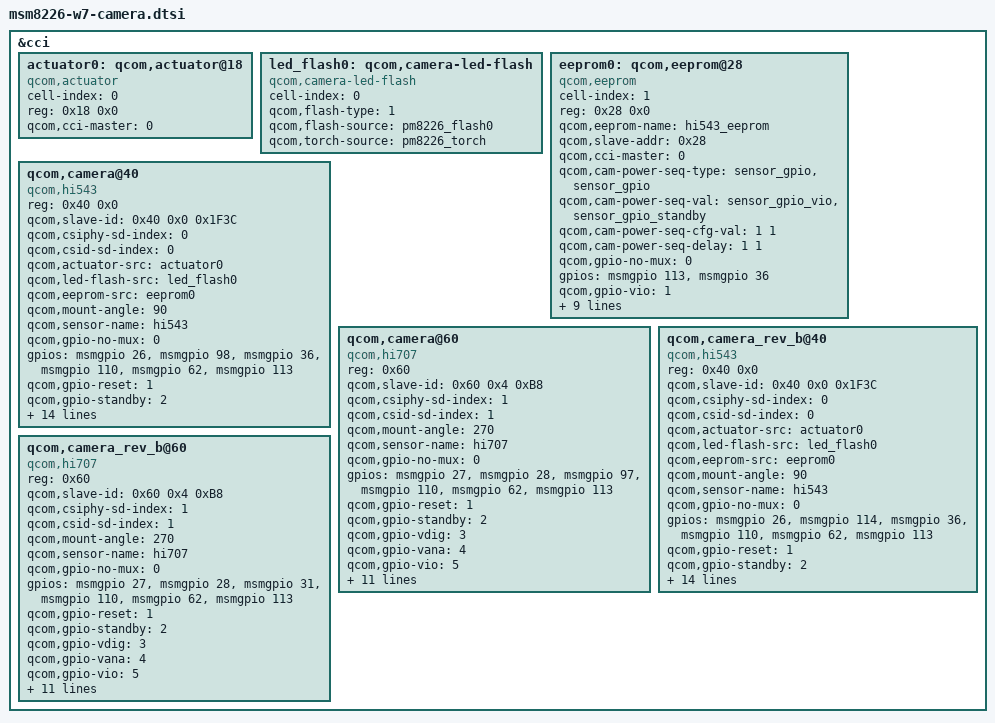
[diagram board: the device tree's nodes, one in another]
/*
 * Copyright (c) 2013, The Linux Foundation. All rights reserved.
 *
 * This program is free software; you can redistribute it and/or modify
 * it under the terms of the GNU General Public License version 2 and
 * only version 2 as published by the Free Software Foundation.
 *
 * This program is distributed in the hope that it will be useful,
 * but WITHOUT ANY WARRANTY; without even the implied warranty of
 * MERCHANTABILITY or FITNESS FOR A PARTICULAR PURPOSE.  See the
 * GNU General Public License for more details.
 */

&cci {
	actuator0: qcom,actuator@18 {
		cell-index = <0>;	//Use Af_main_0 of dw9716 with HI543
		reg = <0x18 0x0>;
		compatible = "qcom,actuator";
		qcom,cci-master = <0>;
	};

	led_flash0: qcom,camera-led-flash {
		cell-index = <0>;
		compatible = "qcom,camera-led-flash";
		qcom,flash-type = <1>;
		qcom,flash-source = <&pm8226_flash0>;
                qcom,torch-source = <&pm8226_torch>;
	};

	eeprom0: qcom,eeprom@28 { //EEPROM READ
		cell-index = <1>;
		reg = <0x28 0x0>;
		qcom,eeprom-name = "hi543_eeprom";
		compatible = "qcom,eeprom";
		qcom,slave-addr = <0x28>;
		qcom,cci-master = <0>;

		qcom,cam-power-seq-type = "sensor_gpio","sensor_gpio";
		qcom,cam-power-seq-val = "sensor_gpio_vio","sensor_gpio_standby";
		qcom,cam-power-seq-cfg-val = <1 1>;
		qcom,cam-power-seq-delay = <1 1>;
		qcom,gpio-no-mux = <0>;
		gpios = <&msmgpio 113 0>,	//1.8V IOVDD
			<&msmgpio 36 0>;		//2.8V VCM
		qcom,gpio-vio = <1>;
		qcom,gpio-standby = <0>;		//CAM_STANDBY
		qcom,gpio-req-tbl-num = <0 1>;
		qcom,gpio-req-tbl-flags = <0 0>;
		qcom,gpio-req-tbl-label = "MAIN_VIO_EN","CAM_STANDBY";

		qcom,num-blocks = <1>;
		qcom,page0 = <0 0x0 1 0x0 1 20>; // valid size, addr, addr_t, data, data_t, delay
		qcom,poll0 = <0 0x0 1 0x0 1 20>;
		qcom,mem0  = <0x06 0x0000 2 0 1 0>; //EEPROM READ
	};

	/* Rev A */
	qcom,camera@40 {
		compatible = "qcom,hi543";
		reg = <0x40 0x0>;
		qcom,slave-id = <0x40 0x0 0x1F3C>;
		qcom,csiphy-sd-index = <0>;
		qcom,csid-sd-index = <0>;
		qcom,actuator-src = <&actuator0>;
		qcom,led-flash-src = <&led_flash0>;
		qcom,eeprom-src = <&eeprom0>;
		qcom,mount-angle = <90>;
		qcom,sensor-name = "hi543";
		qcom,gpio-no-mux = <0>;
		gpios = <&msmgpio 26 0>,
			<&msmgpio 98 0>,
			<&msmgpio 36 0>,
			<&msmgpio 110 0>,	//1.8V DVDD
			<&msmgpio 62 0>,	//2.8V AVDD & 2.8V VCM
			<&msmgpio 113 0>;	//1.8V IOVDD
		qcom,gpio-reset = <1>;
		qcom,gpio-standby = <2>;
		qcom,gpio-vdig = <3>;
		qcom,gpio-vana = <4>;
		qcom,gpio-vio = <5>;
		qcom,gpio-req-tbl-num = <0 1 2 3 4 5>;
		qcom,gpio-req-tbl-flags = <1 0 0 0 0 0>;
		qcom,gpio-req-tbl-label = "CAMIF_MCLK", "CAM_RESET1", "CAM_STANDBY", "MAIN_VDIG_EN", "MAIN_VANA_EN", "MAIN_VIO_EN";
		qcom,csi-lane-assign = <0x4320>;
		qcom,csi-lane-mask = <0x07>;
		qcom,sensor-position = <0>;
		qcom,sensor-mode = <1>;
		qcom,cci-master = <0>;
		status = "okay";
		revision = "...rev_a";
	};
	qcom,camera@60 {
		compatible = "qcom,hi707";
		reg = <0x60>;
		qcom,slave-id = <0x60 0x4 0xB8>;
		qcom,csiphy-sd-index = <1>;
		qcom,csid-sd-index = <1>;
		qcom,mount-angle = <270>;
		qcom,sensor-name = "hi707";
		qcom,gpio-no-mux = <0>;
		gpios = <&msmgpio 27 0>,
			<&msmgpio 28 0>,		//VT_CAM_RESET_N, GPIO 28
			<&msmgpio 97 0>,		//VT_CAM_PWDN, GPIO=97
			<&msmgpio 110 0>,	    //CAM_DVDD_1V8, LDO2_EN=GPIO 110
			<&msmgpio 62 0>,		//CAM_AVDD_2V8, LDO1_EN=GPIO 62
			<&msmgpio 113 0>;	    //CAM_IOVDD_1V8, LDO3_EN=GPIO 113
		qcom,gpio-reset = <1>;
		qcom,gpio-standby = <2>;
		qcom,gpio-vdig = <3>;		// =CAM_DVDD_1V8
		qcom,gpio-vana = <4>;		// =CAM_AVDD_2V8
		qcom,gpio-vio = <5>;		// =CAM_IOVDD_1V8
		qcom,gpio-req-tbl-num = <0 1 2 3 4 5>;
		qcom,gpio-req-tbl-flags = <1 0 0 0 0 0>;
		qcom,gpio-req-tbl-label = "CAMIF_MCLK2", "CAM_RESET2", "CAM_STANDBY2", "MAIN_VDIG_EN2", "MAIN_VANA_EN2", "MAIN_VIO_EN2";
		qcom,csi-lane-assign = <0x4320>;
		qcom,csi-lane-mask = <0x3>;
		qcom,sensor-position = <1>;
		qcom,sensor-mode = <1>;
		qcom,cci-master = <0>;
		status = "okay";
		revision = "...rev_a";
	};
	/* Rev B */
	qcom,camera_rev_b@40 {
		compatible = "qcom,hi543";
		reg = <0x40 0x0>;
		qcom,slave-id = <0x40 0x0 0x1F3C>;
		qcom,csiphy-sd-index = <0>;
		qcom,csid-sd-index = <0>;
		qcom,actuator-src = <&actuator0>;
		qcom,led-flash-src = <&led_flash0>;
		qcom,eeprom-src = <&eeprom0>; 
		qcom,mount-angle = <90>;
		qcom,sensor-name = "hi543";
		qcom,gpio-no-mux = <0>;
		gpios = <&msmgpio 26 0>,
			<&msmgpio 114 0>,	//98 -> 114
			<&msmgpio 36 0>,
			<&msmgpio 110 0>,	//1.8V DVDD
			<&msmgpio 62 0>,	//2.8V AVDD & 2.8V VCM
			<&msmgpio 113 0>;	//1.8V IOVDD
		qcom,gpio-reset = <1>;
		qcom,gpio-standby = <2>;
		qcom,gpio-vdig = <3>;
		qcom,gpio-vana = <4>;
		qcom,gpio-vio = <5>;
		qcom,gpio-req-tbl-num = <0 1 2 3 4 5>;
		qcom,gpio-req-tbl-flags = <1 0 0 0 0 0>;
		qcom,gpio-req-tbl-label = "CAMIF_MCLK", "CAM_RESET1", "CAM_STANDBY", "MAIN_VDIG_EN", "MAIN_VANA_EN", "MAIN_VIO_EN";
		qcom,csi-lane-assign = <0x4320>;
		qcom,csi-lane-mask = <0x07>;
		qcom,sensor-position = <0>;
		qcom,sensor-mode = <1>;
		qcom,cci-master = <0>;
		status = "okay";
		revision = "rev_b...";
	};
	qcom,camera_rev_b@60 {
		compatible = "qcom,hi707";
		reg = <0x60>;
		qcom,slave-id = <0x60 0x4 0xB8>;
		qcom,csiphy-sd-index = <1>;
		qcom,csid-sd-index = <1>;
		qcom,mount-angle = <270>;
		qcom,sensor-name = "hi707";
		qcom,gpio-no-mux = <0>;
		gpios = <&msmgpio 27 0>,
			<&msmgpio 28 0>,		//VT_CAM_RESET_N, GPIO 28
			<&msmgpio 31 0>,		//VT_CAM_PWDN, GPIO=97->31
			<&msmgpio 110 0>,	    //CAM_DVDD_1V8, LDO2_EN=GPIO 110
			<&msmgpio 62 0>,		//CAM_AVDD_2V8, LDO1_EN=GPIO 62
			<&msmgpio 113 0>;	    //CAM_IOVDD_1V8, LDO3_EN=GPIO 113
		qcom,gpio-reset = <1>;
		qcom,gpio-standby = <2>;
		qcom,gpio-vdig = <3>;		// =CAM_DVDD_1V8
		qcom,gpio-vana = <4>;		// =CAM_AVDD_2V8
		qcom,gpio-vio = <5>;		// =CAM_IOVDD_1V8
		qcom,gpio-req-tbl-num = <0 1 2 3 4 5>;
		qcom,gpio-req-tbl-flags = <1 0 0 0 0 0>;
		qcom,gpio-req-tbl-label = "CAMIF_MCLK2", "CAM_RESET2", "CAM_STANDBY2", "MAIN_VDIG_EN2", "MAIN_VANA_EN2", "MAIN_VIO_EN2";
		qcom,csi-lane-assign = <0x4320>;
		qcom,csi-lane-mask = <0x3>;
		qcom,sensor-position = <1>;
		qcom,sensor-mode = <1>;
		qcom,cci-master = <0>;
		status = "okay";
		revision = "rev_b...";
	};
};
